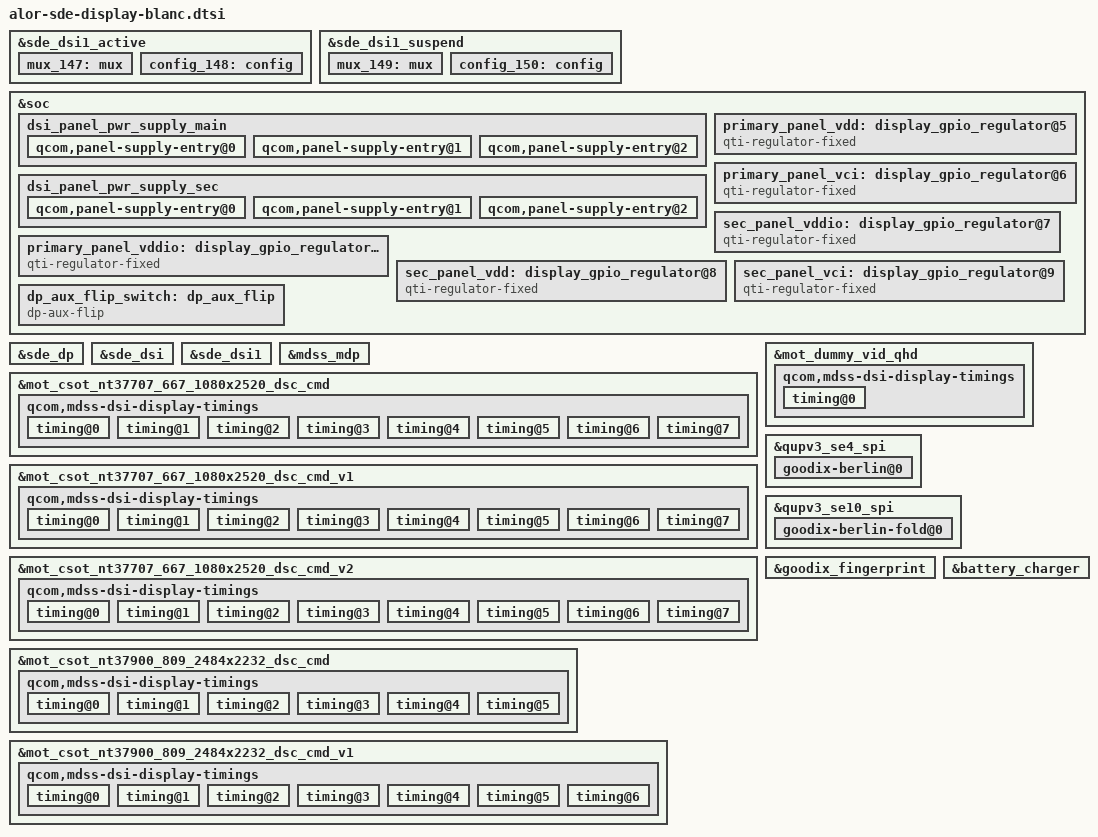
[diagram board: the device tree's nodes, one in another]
// SPDX-License-Identifier: BSD-3-Clause
/*
 * Copyright (c) Qualcomm Technologies, Inc. and/or its subsidiaries.
 */

#include "alor-sde-display.dtsi"
#include "dsi-panel-mot-dummy-qhd-video.dtsi"
#include "dsi-panel-mot-csot-nt37900-809-2484x2232-dsc-cmd-common.dtsi"
#include "dsi-panel-mot-csot-nt37707-667-1080x2520-dsc-cmd-common.dtsi"
#include "dsi-panel-mot-csot-nt37900-809-2484x2232-dsc-cmd-common-v1.dtsi"
#include "dsi-panel-mot-csot-nt37707-667-1080x2520-dsc-cmd-common-v1.dtsi"
#include "dsi-panel-mot-csot-nt37707-667-1080x2520-dsc-cmd-common-v2.dtsi"

&sde_dsi1_active {
	mux_147: mux {
		pins = "gpio88";
		function = "gpio";
	};

	config_148: config {
		pins = "gpio88";
		drive-strength = <8>;   /* 8 mA */
		bias-disable = <0>;   /* no pull */
	};
};

&sde_dsi1_suspend {
	mux_149: mux {
		pins = "gpio88";
		function = "gpio";
	};

	config_150: config {
		pins = "gpio88";
		drive-strength = <2>;   /* 2 mA */
		bias-pull-down;         /* PULL DOWN */
	};
};

&soc {
	dsi_panel_pwr_supply_main: dsi_panel_pwr_supply_main {
		#address-cells = <1>;
		#size-cells = <0>;

		qcom,panel-supply-entry@0 {
			reg = <0>;
			qcom,supply-name = "vddio";
			qcom,supply-min-voltage = <1800000>;
			qcom,supply-max-voltage = <1800000>;
			qcom,supply-enable-load = <300000>;
			qcom,supply-disable-load = <100>;
			qcom,supply-pre-on-sleep = <0>;
			qcom,supply-post-on-sleep = <1>;
			qcom,supply-pre-off-sleep = <0>;
			qcom,supply-post-off-sleep = <0>;
		};
		qcom,panel-supply-entry@1 {
			reg = <1>;
			qcom,supply-name = "vdd";
			qcom,supply-min-voltage = <1200000>;
			qcom,supply-max-voltage = <1200000>;
			qcom,supply-enable-load = <300000>;
			qcom,supply-disable-load = <100>;
			qcom,supply-pre-on-sleep = <0>;
			qcom,supply-post-on-sleep = <1>;
			qcom,supply-pre-off-sleep = <0>;
			qcom,supply-post-off-sleep = <1>;
		};

		qcom,panel-supply-entry@2 {
			reg = <2>;
			qcom,supply-name = "vci";
			qcom,supply-min-voltage = <3000000>;
			qcom,supply-max-voltage = <3000000>;
			qcom,supply-enable-load = <300000>;
			qcom,supply-disable-load = <0>;
			qcom,supply-pre-on-sleep = <0>;
			qcom,supply-post-on-sleep = <0>;
			qcom,supply-pre-off-sleep = <0>;
			qcom,supply-post-off-sleep = <1>;
		};
	};

	dsi_panel_pwr_supply_sec: dsi_panel_pwr_supply_sec {
		#address-cells = <1>;
		#size-cells = <0>;

		qcom,panel-supply-entry@0 {
			reg = <0>;
			qcom,supply-name = "vddio";
			qcom,supply-min-voltage = <1800000>;
			qcom,supply-max-voltage = <1800000>;
			qcom,supply-enable-load = <300000>;
			qcom,supply-disable-load = <100>;
			qcom,supply-pre-on-sleep = <0>;
			qcom,supply-post-on-sleep = <1>;
			qcom,supply-pre-off-sleep = <0>;
			qcom,supply-post-off-sleep = <0>;
		};
		qcom,panel-supply-entry@1 {
			reg = <1>;
			qcom,supply-name = "vdd";
			qcom,supply-min-voltage = <1200000>;
			qcom,supply-max-voltage = <1200000>;
			qcom,supply-enable-load = <300000>;
			qcom,supply-disable-load = <100>;
			qcom,supply-pre-on-sleep = <0>;
			qcom,supply-post-on-sleep = <1>;
			qcom,supply-pre-off-sleep = <0>;
			qcom,supply-post-off-sleep = <1>;
		};

		qcom,panel-supply-entry@2 {
			reg = <2>;
			qcom,supply-name = "vci";
			qcom,supply-min-voltage = <3000000>;
			qcom,supply-max-voltage = <3000000>;
			qcom,supply-enable-load = <300000>;
			qcom,supply-disable-load = <0>;
			qcom,supply-pre-on-sleep = <0>;
			qcom,supply-post-on-sleep = <0>;
			qcom,supply-pre-off-sleep = <0>;
			qcom,supply-post-off-sleep = <1>;
		};
	};

	primary_panel_vddio: display_gpio_regulator@4 {
		compatible = "qti-regulator-fixed";
		regulator-name = "primary_panel_vddio";
		regulator-min-microvolt = <1800000>;
		regulator-max-microvolt = <1800000>;
		regulator-enable-ramp-delay = <233>;
		gpio = <&gpio_expander 2 0>;
		enable-active-high;
		regulator-boot-on;
		depends-on-supply = <&gpio_expander>;
	};
	primary_panel_vdd: display_gpio_regulator@5 {
		compatible = "qti-regulator-fixed";
		regulator-name = "primary_panel_vdd";
		regulator-min-microvolt = <1200000>;
		regulator-max-microvolt = <1200000>;
		regulator-enable-ramp-delay = <233>;
		gpio = <&gpio_expander 0 0>;
		enable-active-high;
		regulator-boot-on;
		depends-on-supply = <&gpio_expander>;
	};
	primary_panel_vci: display_gpio_regulator@6 {
		compatible = "qti-regulator-fixed";
		regulator-name = "primary_panel_vci";
		regulator-min-microvolt = <3000000>;
		regulator-max-microvolt = <3000000>;
		regulator-enable-ramp-delay = <233>;
		gpio = <&gpio_expander 1 0>;
		enable-active-high;
		regulator-boot-on;
		depends-on-supply = <&gpio_expander>;
	};

	sec_panel_vddio: display_gpio_regulator@7 {
		compatible = "qti-regulator-fixed";
		regulator-name = "sec_panel_vddio";
		regulator-min-microvolt = <1800000>;
		regulator-max-microvolt = <1800000>;
		regulator-enable-ramp-delay = <233>;
		gpio = <&gpio_expander 7 0>;
		enable-active-high;
		regulator-boot-on;
		depends-on-supply = <&gpio_expander>;
	};
	sec_panel_vdd: display_gpio_regulator@8 {
		compatible = "qti-regulator-fixed";
		regulator-name = "sec_panel_vdd";
		regulator-min-microvolt = <1200000>;
		regulator-max-microvolt = <1200000>;
		regulator-enable-ramp-delay = <233>;
		gpio = <&gpio_expander 5 0>;
		enable-active-high;
		regulator-boot-on;
		depends-on-supply = <&gpio_expander>;
	};
	sec_panel_vci: display_gpio_regulator@9 {
		compatible = "qti-regulator-fixed";
		regulator-name = "sec_panel_vci";
		regulator-min-microvolt = <3000000>;
		regulator-max-microvolt = <3000000>;
		regulator-enable-ramp-delay = <233>;
		gpio = <&gpio_expander 6 0>;
		enable-active-high;
		regulator-boot-on;
		depends-on-supply = <&gpio_expander>;
	};

	dp_aux_flip_switch: dp_aux_flip {
		compatible = "dp-aux-flip";
		mmi,aux-switch-enable-gpio = <&tlmm 119 0>;
		mmi,aux-switch-flip-gpio = <&tlmm 120 0>;
	};
};

&sde_dp {
	status = "ok";
	qcom,dp-downgrade;
	mmi,aux-switch-enable-gpio = <&tlmm 119 0>;
	mmi,aux-switch-flip-gpio = <&tlmm 120 0>;
	qcom,dp-aux-switch = <&dp_aux_flip_switch>;
};

&sde_dsi {
	vddio-supply = <&primary_panel_vddio>;
	vdd-supply = <&primary_panel_vdd>;
	vci-supply = <&primary_panel_vci>;
	pinctrl-names = "panel_active", "panel_suspend";
	pinctrl-0 = <&sde_dsi_active &sde_te_active>;
	pinctrl-1 = <&sde_dsi_suspend &sde_te_suspend>;
	/delete-property/ pinctrl-2;
};

&sde_dsi1 {
	vddio-supply = <&sec_panel_vddio>;
	vdd-supply = <&sec_panel_vdd>;
	vci-supply = <&sec_panel_vci>;

	pinctrl-names = "panel_active", "panel_suspend";
	pinctrl-0 = <&sde_dsi1_active &sde_te1_active>;
	pinctrl-1 = <&sde_dsi1_suspend &sde_te1_suspend>;
	/delete-property/ pinctrl-2;
};

&mdss_mdp {
	connectors = <&sde_dsi &sde_dsi1 &smmu_sde_unsec &smmu_sde_sec &sde_wb0 &sde_wb1 &sde_dp>;
};


&mot_csot_nt37707_667_1080x2520_dsc_cmd {
	qcom,dsi-select-sec-clocks = "pll_byte_clk0", "pll_dsi_clk0";
	qcom,panel-supply-entries = <&dsi_panel_pwr_supply_main>;
	qcom,panel-sec-supply-entries = <&dsi_panel_pwr_supply_sec>;
	qcom,mdss-dsi-no-panel-on-read-support;
	qcom,mdss-dsi-bl-pmic-control-type = "bl_ctrl_dcs";
	qcom,mdss-dsi-sec-bl-pmic-control-type = "bl_ctrl_dcs";
	qcom,mdss-dsi-bl-min-level = <420>;
	qcom,mdss-dsi-bl-max-level = <15600>;
	qcom,mdss-dsi-bl-default-level = <7368>;
	qcom,mdss-brightness-max-level = <15600>;
	qcom,platform-reset-gpio = <&tlmm 146 0>;
	qcom,platform-sec-reset-gpio = <&tlmm 88 0>;
	//qcom,platform-te-gpio = <&tlmm 55 0>;
	qcom,bl-dsc-cmd-state = "dsi_hs_mode";
	qcom,mdss-dsi-bl-inverted-dbv;
	qcom,mdss-dsi-bl-is-exponent;

	qcom,mdss-dsi-panel-status-check-mode = "reg_read";
	qcom,mdss-dsi-panel-status-command = [06 01 00 01 00 00 01 0a];
	qcom,mdss-dsi-panel-status-command-state = "dsi_lp_mode";
	qcom,mdss-dsi-panel-status-value = <0x9c>;
	qcom,mdss-dsi-panel-status-read-length = <1>;
	qcom,esd-check-enabled;
	qcom,cellid-read-enabled;
	qcom,mdss-dsi-panel-cellid-read-length = <36>;
	qcom,mdss-dsi-panel-cellid-offset = <13>;
	qcom,mdss-dsi-panel-cellid-command = [
		06 01 00 01 00 00 01 AC];

	qcom,mdss-dsi-panel-hdr-enabled;
	qcom,mdss-dsi-panel-hdr-color-primaries = <15600 16450 34000
	        16000 13250 34500 7500 3000>;
	qcom,mdss-dsi-panel-peak-brightness = <15000000>;
	qcom,mdss-dsi-panel-blackness-level = <1>;

	//qcom,apl-enabled;
	//qcom,mdss-dsi-panel-APL-THRESHOLD-BL = <14258>;
	//qcom,mdss-dsi-panel-apl-on-command = [
	//	39 00 00 00 00 00 03 5F 00 01];
	//qcom,mdss-dsi-panel-apl-off-command = [
	//	39 00 00 00 00 00 03 5F 00 00];

	qcom,mdss-dsi-panel-AOD-report-enabled;

	//qcom,ulps-enabled;
	qcom,mdss-dsi-display-timings {
		timing@0 { //60
			qcom,framerate-group-no-duplicated;
			qcom,framerate-group-120hz-based;
			qcom,mdss-dsi-panel-clockrate = <515880000>;
			qcom,display-topology = <2 2 1>;
			qcom,default-topology-index = <0>;
			qcom,mdss-dsi-panel-phy-timings = [00 13 05 04 13 1E 05
							05 06 02 04 00 12 0A];
		};
		timing@1 { //120
			qcom,framerate-group-no-duplicated;
			qcom,framerate-group-120hz-based;
			qcom,mdss-dsi-panel-clockrate = <1031750000>;
			qcom,display-topology = <2 2 1>;
			qcom,default-topology-index = <0>;
			qcom,mdss-dsi-panel-phy-timings = [00 22 09 09 19 17 09
							09 09 02 04 00 1D 0E];
		};
		timing@2 { //165
			qcom,framerate-group-no-duplicated;
			qcom,mdss-dsi-panel-clockrate = <1418660000>;
			qcom,display-topology = <2 2 1>;
			qcom,default-topology-index = <0>;
			qcom,mdss-dsi-panel-phy-timings = [00 2E 0C 0C 1D 1B 0C
							0D 0B 02 04 00 25 11];
		};
		timing@3 { //90
			qcom,framerate-group-no-duplicated;
			qcom,framerate-group-90hz-based;
			qcom,mdss-dsi-panel-clockrate = <773820000>;
			qcom,display-topology = <2 2 1>;
			qcom,default-topology-index = <0>;
			qcom,mdss-dsi-panel-phy-timings = [00 1A 07 06 16 21 07
							07 07 02 04 00 17 0C];
		};
		timing@4 { //30
			qcom,framerate-group-no-duplicated;
			qcom,framerate-group-120hz-based;
			qcom,mdss-dsi-panel-clockrate = <1031750000>;
			qcom,display-topology = <2 2 1>;
			qcom,default-topology-index = <0>;
			qcom,mdss-dsi-panel-phy-timings = [00 22 09 09 19 17 09
							09 09 02 04 00 1D 0E];
		};
		timing@5 { //24
			qcom,framerate-group-no-duplicated;
			qcom,framerate-group-120hz-based;
			qcom,mdss-dsi-panel-clockrate = <1031750000>;
			qcom,display-topology = <2 2 1>;
			qcom,default-topology-index = <0>;
			qcom,mdss-dsi-panel-phy-timings = [00 22 09 09 19 17 09
							09 09 02 04 00 1D 0E];
		};
		timing@6 { //10
			qcom,framerate-group-special-idle-10hz;
			qcom,mdss-dsi-panel-clockrate = <1031750000>;
			qcom,display-topology = <2 2 1>;
			qcom,default-topology-index = <0>;
			qcom,mdss-dsi-panel-phy-timings = [00 22 09 09 19 17 09
							09 09 02 04 00 1D 0E];
		};
		timing@7 { //1
			qcom,framerate-group-special-idle-1hz;
			qcom,mdss-dsi-panel-clockrate = <1031750000>;
			qcom,display-topology = <2 2 1>;
			qcom,default-topology-index = <0>;
			qcom,mdss-dsi-panel-phy-timings = [00 22 09 09 19 17 09
							09 09 02 04 00 1D 0E];
		};
	};
};

&mot_csot_nt37707_667_1080x2520_dsc_cmd_v1 {
	qcom,dsi-select-sec-clocks = "pll_byte_clk0", "pll_dsi_clk0";
	qcom,panel-supply-entries = <&dsi_panel_pwr_supply_main>;
	qcom,panel-sec-supply-entries = <&dsi_panel_pwr_supply_sec>;
	qcom,mdss-dsi-no-panel-on-read-support;
	qcom,mdss-dsi-bl-pmic-control-type = "bl_ctrl_dcs";
	qcom,mdss-dsi-sec-bl-pmic-control-type = "bl_ctrl_dcs";
	qcom,mdss-dsi-bl-min-level = <420>;
	qcom,mdss-dsi-bl-max-level = <15600>;
	qcom,mdss-dsi-bl-default-level = <7368>;
	qcom,mdss-brightness-max-level = <15600>;
	qcom,platform-reset-gpio = <&tlmm 146 0>;
	qcom,platform-sec-reset-gpio = <&tlmm 88 0>;
	//qcom,platform-te-gpio = <&tlmm 55 0>;
	qcom,bl-dsc-cmd-state = "dsi_hs_mode";
	qcom,mdss-dsi-bl-inverted-dbv;
	qcom,mdss-dsi-bl-is-exponent;

	qcom,mdss-dsi-panel-status-check-mode = "reg_read";
	qcom,mdss-dsi-panel-status-command = [06 01 00 01 00 00 01 0a];
	qcom,mdss-dsi-panel-status-command-state = "dsi_lp_mode";
	qcom,mdss-dsi-panel-status-value = <0x9c>;
	qcom,mdss-dsi-panel-status-read-length = <1>;
	qcom,esd-check-enabled;
	qcom,cellid-read-enabled;
	qcom,mdss-dsi-panel-cellid-read-length = <36>;
	qcom,mdss-dsi-panel-cellid-offset = <13>;
	qcom,mdss-dsi-panel-cellid-command = [
		06 01 00 01 00 00 01 AC];

	qcom,mdss-dsi-panel-hdr-enabled;
	qcom,mdss-dsi-panel-hdr-color-primaries = <15600 16450 34000
	        16000 13250 34500 7500 3000>;
	qcom,mdss-dsi-panel-peak-brightness = <15000000>;
	qcom,mdss-dsi-panel-blackness-level = <1>;

	//qcom,apl-enabled;
	//qcom,mdss-dsi-panel-APL-THRESHOLD-BL = <14258>;
	//qcom,mdss-dsi-panel-apl-on-command = [
	//	39 00 00 00 00 00 03 5F 00 01];
	//qcom,mdss-dsi-panel-apl-off-command = [
	//	39 00 00 00 00 00 03 5F 00 00];

	qcom,mdss-dsi-panel-AOD-report-enabled;

	//qcom,ulps-enabled;
	qcom,mdss-dsi-display-timings {
		timing@0 { //60
			qcom,framerate-group-no-duplicated;
			qcom,framerate-group-120hz-based;
			qcom,mdss-dsi-panel-clockrate = <515880000>;
			qcom,display-topology = <2 2 1>;
			qcom,default-topology-index = <0>;
			qcom,mdss-dsi-panel-phy-timings = [00 13 05 04 13 1E 05
							05 06 02 04 00 12 0A];
		};
		timing@1 { //120
			qcom,framerate-group-no-duplicated;
			qcom,framerate-group-120hz-based;
			qcom,mdss-dsi-panel-clockrate = <1031750000>;
			qcom,display-topology = <2 2 1>;
			qcom,default-topology-index = <0>;
			qcom,mdss-dsi-panel-phy-timings = [00 22 09 09 19 17 09
							09 09 02 04 00 1D 0E];
		};
		timing@2 { //165
			qcom,framerate-group-no-duplicated;
			qcom,mdss-dsi-panel-clockrate = <1418660000>;
			qcom,display-topology = <2 2 1>;
			qcom,default-topology-index = <0>;
			qcom,mdss-dsi-panel-phy-timings = [00 2E 0C 0C 1D 1B 0C
							0D 0B 02 04 00 25 11];
		};
		timing@3 { //90
			qcom,framerate-group-no-duplicated;
			qcom,framerate-group-90hz-based;
			qcom,mdss-dsi-panel-clockrate = <773820000>;
			qcom,display-topology = <2 2 1>;
			qcom,default-topology-index = <0>;
			qcom,mdss-dsi-panel-phy-timings = [00 1A 07 06 16 21 07
							07 07 02 04 00 17 0C];
		};
		timing@4 { //30
			qcom,framerate-group-no-duplicated;
			qcom,framerate-group-120hz-based;
			qcom,mdss-dsi-panel-clockrate = <1031750000>;
			qcom,display-topology = <2 2 1>;
			qcom,default-topology-index = <0>;
			qcom,mdss-dsi-panel-phy-timings = [00 22 09 09 19 17 09
							09 09 02 04 00 1D 0E];
		};
		timing@5 { //24
			qcom,framerate-group-no-duplicated;
			qcom,framerate-group-120hz-based;
			qcom,mdss-dsi-panel-clockrate = <1031750000>;
			qcom,display-topology = <2 2 1>;
			qcom,default-topology-index = <0>;
			qcom,mdss-dsi-panel-phy-timings = [00 22 09 09 19 17 09
							09 09 02 04 00 1D 0E];
		};
		timing@6 { //10
			qcom,framerate-group-special-idle-10hz;
			qcom,mdss-dsi-panel-clockrate = <1031750000>;
			qcom,display-topology = <2 2 1>;
			qcom,default-topology-index = <0>;
			qcom,mdss-dsi-panel-phy-timings = [00 22 09 09 19 17 09
							09 09 02 04 00 1D 0E];
		};
		timing@7 { //1
			qcom,framerate-group-special-idle-1hz;
			qcom,mdss-dsi-panel-clockrate = <1031750000>;
			qcom,display-topology = <2 2 1>;
			qcom,default-topology-index = <0>;
			qcom,mdss-dsi-panel-phy-timings = [00 22 09 09 19 17 09
							09 09 02 04 00 1D 0E];
		};
	};
};

&mot_csot_nt37707_667_1080x2520_dsc_cmd_v2 {
	qcom,dsi-select-sec-clocks = "pll_byte_clk0", "pll_dsi_clk0";
	qcom,panel-supply-entries = <&dsi_panel_pwr_supply_main>;
	qcom,panel-sec-supply-entries = <&dsi_panel_pwr_supply_sec>;
	qcom,mdss-dsi-no-panel-on-read-support;
	qcom,mdss-dsi-bl-pmic-control-type = "bl_ctrl_dcs";
	qcom,mdss-dsi-sec-bl-pmic-control-type = "bl_ctrl_dcs";
	qcom,mdss-dsi-bl-min-level = <420>;
	qcom,mdss-dsi-bl-max-level = <15600>;
	qcom,mdss-dsi-bl-default-level = <7368>;
	qcom,mdss-brightness-max-level = <15600>;
	qcom,platform-reset-gpio = <&tlmm 146 0>;
	qcom,platform-sec-reset-gpio = <&tlmm 88 0>;
	//qcom,platform-te-gpio = <&tlmm 55 0>;
	qcom,bl-dsc-cmd-state = "dsi_hs_mode";
	qcom,mdss-dsi-bl-inverted-dbv;
	qcom,mdss-dsi-bl-is-exponent;

	qcom,mdss-dsi-panel-status-check-mode = "reg_read";
	qcom,mdss-dsi-panel-status-command = [06 01 00 01 00 00 01 0a];
	qcom,mdss-dsi-panel-status-command-state = "dsi_lp_mode";
	qcom,mdss-dsi-panel-status-value = <0x9c>;
	qcom,mdss-dsi-panel-status-read-length = <1>;
	qcom,esd-check-enabled;
	qcom,cellid-read-enabled;
	qcom,mdss-dsi-panel-cellid-read-length = <36>;
	qcom,mdss-dsi-panel-cellid-offset = <13>;
	qcom,mdss-dsi-panel-cellid-command = [
		06 01 00 01 00 00 01 AC];

	qcom,mdss-dsi-panel-hdr-enabled;
	qcom,mdss-dsi-panel-hdr-color-primaries = <15600 16450 34000
	        16000 13250 34500 7500 3000>;
	qcom,mdss-dsi-panel-peak-brightness = <15000000>;
	qcom,mdss-dsi-panel-blackness-level = <1>;

	//qcom,apl-enabled;
	//qcom,mdss-dsi-panel-APL-THRESHOLD-BL = <14258>;
	//qcom,mdss-dsi-panel-apl-on-command = [
	//	39 00 00 00 00 00 03 5F 00 01];
	//qcom,mdss-dsi-panel-apl-off-command = [
	//	39 00 00 00 00 00 03 5F 00 00];

	qcom,mdss-dsi-panel-AOD-report-enabled;

	//qcom,ulps-enabled;
	qcom,mdss-dsi-display-timings {
		timing@0 { //60
			qcom,framerate-group-no-duplicated;
			qcom,framerate-group-120hz-based;
			qcom,mdss-dsi-panel-clockrate = <515880000>;
			qcom,display-topology = <2 2 1>;
			qcom,default-topology-index = <0>;
			qcom,mdss-dsi-panel-phy-timings = [00 13 05 04 13 1E 05
							05 06 02 04 00 12 0A];
		};
		timing@1 { //120
			qcom,framerate-group-no-duplicated;
			qcom,framerate-group-120hz-based;
			qcom,mdss-dsi-panel-clockrate = <1031750000>;
			qcom,display-topology = <2 2 1>;
			qcom,default-topology-index = <0>;
			qcom,mdss-dsi-panel-phy-timings = [00 22 09 09 19 17 09
							09 09 02 04 00 1D 0E];
		};
		timing@2 { //165
			qcom,framerate-group-no-duplicated;
			qcom,mdss-dsi-panel-clockrate = <1418660000>;
			qcom,display-topology = <2 2 1>;
			qcom,default-topology-index = <0>;
			qcom,mdss-dsi-panel-phy-timings = [00 2E 0C 0C 1D 1B 0C
							0D 0B 02 04 00 25 11];
		};
		timing@3 { //90
			qcom,framerate-group-no-duplicated;
			qcom,framerate-group-90hz-based;
			qcom,mdss-dsi-panel-clockrate = <773820000>;
			qcom,display-topology = <2 2 1>;
			qcom,default-topology-index = <0>;
			qcom,mdss-dsi-panel-phy-timings = [00 1A 07 06 16 21 07
							07 07 02 04 00 17 0C];
		};
		timing@4 { //30
			qcom,framerate-group-no-duplicated;
			qcom,framerate-group-120hz-based;
			qcom,mdss-dsi-panel-clockrate = <1031750000>;
			qcom,display-topology = <2 2 1>;
			qcom,default-topology-index = <0>;
			qcom,mdss-dsi-panel-phy-timings = [00 22 09 09 19 17 09
							09 09 02 04 00 1D 0E];
		};
		timing@5 { //24
			qcom,framerate-group-no-duplicated;
			qcom,framerate-group-120hz-based;
			qcom,mdss-dsi-panel-clockrate = <1031750000>;
			qcom,display-topology = <2 2 1>;
			qcom,default-topology-index = <0>;
			qcom,mdss-dsi-panel-phy-timings = [00 22 09 09 19 17 09
							09 09 02 04 00 1D 0E];
		};
		timing@6 { //10
			qcom,framerate-group-special-idle-10hz;
			qcom,mdss-dsi-panel-clockrate = <1031750000>;
			qcom,display-topology = <2 2 1>;
			qcom,default-topology-index = <0>;
			qcom,mdss-dsi-panel-phy-timings = [00 22 09 09 19 17 09
							09 09 02 04 00 1D 0E];
		};
		timing@7 { //1
			qcom,framerate-group-special-idle-1hz;
			qcom,mdss-dsi-panel-clockrate = <1031750000>;
			qcom,display-topology = <2 2 1>;
			qcom,default-topology-index = <0>;
			qcom,mdss-dsi-panel-phy-timings = [00 22 09 09 19 17 09
							09 09 02 04 00 1D 0E];
		};
	};
};

&mot_csot_nt37900_809_2484x2232_dsc_cmd {
	qcom,dsi-select-clocks = "pll_byte_clk1", "pll_dsi_clk1";
	qcom,panel-supply-entries = <&dsi_panel_pwr_supply_main>;
	qcom,mdss-dsi-no-panel-on-read-support;
	qcom,mdss-dsi-bl-pmic-control-type = "bl_ctrl_dcs";
	qcom,mdss-dsi-bl-min-level = <3>;
	qcom,mdss-dsi-bl-max-level = <15600>;
	qcom,mdss-dsi-bl-default-level = <7368>;
	qcom,mdss-brightness-max-level = <15600>;
	qcom,platform-reset-gpio = <&tlmm 146 0>;
	qcom,bl-dsc-cmd-state = "dsi_hs_mode";
	qcom,mdss-dsi-bl-inverted-dbv;
	qcom,mdss-dsi-bl-is-exponent;

	qcom,mdss-dsi-panel-status-check-mode = "reg_read";
	qcom,mdss-dsi-panel-status-command = [06 01 00 01 00 00 01 0a];
	qcom,mdss-dsi-panel-status-command-state = "dsi_lp_mode";
	qcom,mdss-dsi-panel-status-value = <0x9c>;
	qcom,mdss-dsi-panel-status-read-length = <1>;
	qcom,esd-check-enabled;
	qcom,cellid-read-enabled;
	qcom,mdss-dsi-panel-cellid-read-length = <36>;
	qcom,mdss-dsi-panel-cellid-offset = <13>;
	qcom,mdss-dsi-panel-cellid-command = [
		06 01 00 01 00 00 01 AC];

	qcom,mdss-dsi-panel-hdr-enabled;
	qcom,mdss-dsi-panel-hdr-color-primaries = <15600 16450 34000
	        16000 13250 34500 7500 3000>;
	qcom,mdss-dsi-panel-peak-brightness = <15000000>;
	qcom,mdss-dsi-panel-blackness-level = <1>;

	//qcom,ulps-enabled;
	qcom,mdss-dsi-display-timings {
		timing@0 { //120
			qcom,framerate-group-no-duplicated;
			qcom,framerate-group-120hz-based;
			qcom,mdss-dsi-panel-clockrate = <1560700000>;
			qcom,display-topology = <2 2 1>;
			qcom,default-topology-index = <0>;
			qcom,mdss-dsi-panel-phy-timings = [00 36 0D 0D 1F 1C 0D
							0E 0C 02 04 00 2A 12];
		};
		timing@1 { //90
			qcom,framerate-group-no-duplicated;
			qcom,framerate-group-90hz-based;
			qcom,mdss-mdp-transfer-time-us = <7144>;
			qcom,display-topology = <2 2 1>;
			qcom,default-topology-index = <0>;
			qcom,mdss-dsi-panel-phy-timings = [00 36 0D 0D 1F 1C 0D
							0E 0C 02 04 00 2A 12];
		};
		timing@2 { //60
			qcom,framerate-group-no-duplicated;
			qcom,framerate-group-120hz-based;
			qcom,mdss-mdp-transfer-time-us = <12500>;
			qcom,display-topology = <2 2 1>;
			qcom,default-topology-index = <0>;
			qcom,mdss-dsi-panel-phy-timings = [00 1E 08 07 18 22 08
							08 08 02 04 00 1A 0D];
		};
		timing@3 { //30
			qcom,framerate-group-no-duplicated;
			qcom,framerate-group-120hz-based;
			qcom,mdss-dsi-panel-clockrate = <1560700000>;
			qcom,display-topology = <2 2 1>;
			qcom,default-topology-index = <0>;
			qcom,mdss-dsi-panel-phy-timings = [00 36 0D 0D 1F 1C 0D
							0E 0C 02 04 00 2A 12];
		};
		timing@4 { //24
			qcom,framerate-group-no-duplicated;
			qcom,framerate-group-120hz-based;
			qcom,mdss-dsi-panel-clockrate = <1560700000>;
			qcom,display-topology = <2 2 1>;
			qcom,default-topology-index = <0>;
			qcom,mdss-dsi-panel-phy-timings = [00 36 0D 0D 1F 1C 0D
							0E 0C 02 04 00 2A 12];
		};
		timing@5 { //10
			qcom,framerate-group-special-idle-10hz;
			qcom,mdss-dsi-panel-clockrate = <1560700000>;
			qcom,display-topology = <2 2 1>;
			qcom,default-topology-index = <0>;
			qcom,mdss-dsi-panel-phy-timings = [00 36 0D 0D 1F 1C 0D
							0E 0C 02 04 00 2A 12];
		};
	};
};

&mot_csot_nt37900_809_2484x2232_dsc_cmd_v1 {
	qcom,dsi-select-clocks = "pll_byte_clk1", "pll_dsi_clk1";
	qcom,panel-supply-entries = <&dsi_panel_pwr_supply_main>;
	qcom,mdss-dsi-no-panel-on-read-support;
	qcom,mdss-dsi-bl-pmic-control-type = "bl_ctrl_dcs";
	qcom,mdss-dsi-bl-min-level = <3>;
	qcom,mdss-dsi-bl-max-level = <15600>;
	qcom,mdss-dsi-bl-default-level = <7368>;
	qcom,mdss-brightness-max-level = <15600>;
	qcom,platform-reset-gpio = <&tlmm 146 0>;
	qcom,bl-dsc-cmd-state = "dsi_hs_mode";
	qcom,mdss-dsi-bl-inverted-dbv;
	qcom,mdss-dsi-bl-is-exponent;

	qcom,mdss-dsi-panel-status-check-mode = "reg_read";
	qcom,mdss-dsi-panel-status-command = [06 01 00 01 00 00 01 0a];
	qcom,mdss-dsi-panel-status-command-state = "dsi_lp_mode";
	qcom,mdss-dsi-panel-status-value = <0x9c>;
	qcom,mdss-dsi-panel-status-read-length = <1>;
	qcom,esd-check-enabled;
	qcom,cellid-read-enabled;
	qcom,mdss-dsi-panel-cellid-read-length = <36>;
	qcom,mdss-dsi-panel-cellid-offset = <13>;
	qcom,mdss-dsi-panel-cellid-command = [
		06 01 00 01 00 00 01 AC];

	qcom,mdss-dsi-panel-hdr-enabled;
	qcom,mdss-dsi-panel-hdr-color-primaries = <15600 16450 34000
	        16000 13250 34500 7500 3000>;
	qcom,mdss-dsi-panel-peak-brightness = <15000000>;
	qcom,mdss-dsi-panel-blackness-level = <1>;

	//qcom,ulps-enabled;
	qcom,partition-refreshrate-enabled;
	qcom,mdss-dsi-panel-boundaryLine-reg-count = <8>;
	qcom,mdss-dsi-panel-partition-refreshrate-slice-h = <8>;
	qcom,mdss-dsi-panel-partition-refreshrate-min-boundaryLine = <0>;
	qcom,mdss-dsi-panel-partition-refreshrate-max-boundaryLine = <2232>;
	qcom,mdss-dsi-panel-partition-refreshrate-under-dfps-list = <120 90>;

	qcom,mdss-dsi-display-timings {
		timing@0 { //60
			qcom,framerate-group-no-duplicated;
			qcom,framerate-group-120hz-based;
			qcom,mdss-mdp-transfer-time-us = <12500>;
			qcom,display-topology = <2 2 1>;
			qcom,default-topology-index = <0>;
			qcom,mdss-dsi-panel-phy-timings = [00 1E 08 07 18 22 08
							08 08 02 04 00 1A 0D];
		};
		timing@1 { //120
			qcom,framerate-group-no-duplicated;
			qcom,framerate-group-120hz-based;
			qcom,mdss-dsi-panel-clockrate = <1560700000>;
			qcom,display-topology = <2 2 1>;
			qcom,default-topology-index = <0>;
			qcom,mdss-dsi-panel-phy-timings = [00 36 0D 0D 1F 1C 0D
							0E 0C 02 04 00 2A 12];
		};
		timing@2 { //90
			qcom,framerate-group-no-duplicated;
			qcom,framerate-group-90hz-based;
			qcom,mdss-mdp-transfer-time-us = <7144>;
			qcom,display-topology = <2 2 1>;
			qcom,default-topology-index = <0>;
			qcom,mdss-dsi-panel-phy-timings = [00 36 0D 0D 1F 1C 0D
							0E 0C 02 04 00 2A 12];
		};
		timing@3 { //30
			qcom,framerate-group-no-duplicated;
			qcom,framerate-group-120hz-based;
			qcom,mdss-dsi-panel-clockrate = <1560700000>;
			qcom,display-topology = <2 2 1>;
			qcom,default-topology-index = <0>;
			qcom,mdss-dsi-panel-phy-timings = [00 36 0D 0D 1F 1C 0D
							0E 0C 02 04 00 2A 12];
		};
		timing@4 { //24
			qcom,framerate-group-no-duplicated;
			qcom,framerate-group-120hz-based;
			qcom,mdss-dsi-panel-clockrate = <1560700000>;
			qcom,display-topology = <2 2 1>;
			qcom,default-topology-index = <0>;
			qcom,mdss-dsi-panel-phy-timings = [00 36 0D 0D 1F 1C 0D
							0E 0C 02 04 00 2A 12];
		};
		timing@5 { //10
			qcom,framerate-group-special-idle-10hz;
			qcom,mdss-dsi-panel-clockrate = <1560700000>;
			qcom,display-topology = <2 2 1>;
			qcom,default-topology-index = <0>;
			qcom,mdss-dsi-panel-phy-timings = [00 36 0D 0D 1F 1C 0D
							0E 0C 02 04 00 2A 12];
		};
		timing@6 { //1
			qcom,framerate-group-special-idle-1hz;
			qcom,mdss-dsi-panel-clockrate = <1560700000>;
			qcom,display-topology = <2 2 1>;
			qcom,default-topology-index = <0>;
			qcom,mdss-dsi-panel-phy-timings = [00 36 0D 0D 1F 1C 0D
							0E 0C 02 04 00 2A 12];
		};
	};
};

&mot_dummy_vid_qhd {
	qcom,dsi-select-clocks = "pll_byte_clk1", "pll_dsi_clk1";
	qcom,dsi-ctrl-num = <1>;
	qcom,dsi-phy-num = <1>;
	qcom,platform-reset-gpio = <&tlmm 146 0>;
	qcom,mdss-dsi-display-timings {
		timing@0 {
                       qcom,mdss-dsi-panel-width = <1080>;
                       qcom,mdss-dsi-panel-height = <2400>;
			qcom,display-topology = <1 0 1>;
			qcom,default-topology-index = <0>;
		};
	};
};

&sde_dsi {
	qcom,dsi-default-panel = <&mot_dummy_vid_qhd>;
};

&qupv3_se4_spi {
	goodix-berlin@0 {
		panel = <
			&mot_csot_nt37900_809_2484x2232_dsc_cmd_v1
			&mot_csot_nt37900_809_2484x2232_dsc_cmd>;
	};
};

&qupv3_se10_spi {
	goodix-berlin-fold@0 {
		panel = <
			&mot_csot_nt37707_667_1080x2520_dsc_cmd_v2
			&mot_csot_nt37707_667_1080x2520_dsc_cmd_v1
			&mot_csot_nt37707_667_1080x2520_dsc_cmd>;
	};
};

&goodix_fingerprint {
	qcom,display-panels = <&mot_csot_nt37900_809_2484x2232_dsc_cmd_v1
				&mot_csot_nt37900_809_2484x2232_dsc_cmd>;
	qcom,display-panels-fold= <&mot_csot_nt37707_667_1080x2520_dsc_cmd_v2
				&mot_csot_nt37707_667_1080x2520_dsc_cmd_v1
				&mot_csot_nt37707_667_1080x2520_dsc_cmd>;
};

&battery_charger {
        qcom,display-panels = <&mot_csot_nt37900_809_2484x2232_dsc_cmd_v1
                               &mot_csot_nt37900_809_2484x2232_dsc_cmd>;
        qcom,display-panels-fold = <&mot_csot_nt37707_667_1080x2520_dsc_cmd_v2
                                    &mot_csot_nt37707_667_1080x2520_dsc_cmd_v1
                                    &mot_csot_nt37707_667_1080x2520_dsc_cmd>;
};
